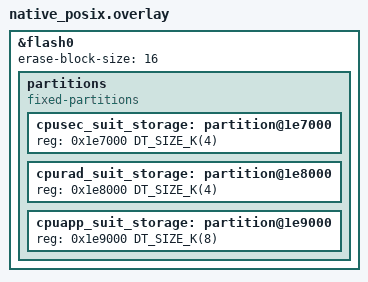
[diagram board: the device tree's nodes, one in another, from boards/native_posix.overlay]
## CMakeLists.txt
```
#
# Copyright (c) 2024 Nordic Semiconductor ASA
#
# SPDX-License-Identifier: LicenseRef-Nordic-5-Clause
#

cmake_minimum_required(VERSION 3.20.0)

find_package(Zephyr REQUIRED HINTS $ENV{ZEPHYR_BASE})

project(integration_test_suit_storage_nrf54h20)
include(../cmake/test_template.cmake)

target_include_directories(app PRIVATE
  ${SUIT_SUBSYS_DIR}/storage/include
)

target_sources(app PRIVATE
  ${SUIT_SUBSYS_DIR}/storage/src/suit_storage_encode.c
  ${SUIT_SUBSYS_DIR}/storage/src/suit_storage_envelope.c
  ${SUIT_SUBSYS_DIR}/storage/src/suit_storage_flags.c
  ${SUIT_SUBSYS_DIR}/storage/src/suit_storage_mpi.c
  # Use nRF54H20-specific implementation.
  ${SUIT_SUBSYS_DIR}/storage/src/suit_storage_nrf54h20.c
  ${SUIT_SUBSYS_DIR}/storage/src/suit_storage_nvv.c
  ${SUIT_SUBSYS_DIR}/storage/src/suit_storage_report.c
  ${SUIT_SUBSYS_DIR}/storage/src/suit_storage_update.c
  )

target_include_directories(app PRIVATE
  ${SUIT_SUBSYS_DIR}/storage/include
  )

zephyr_compile_definitions(
  CONFIG_SUIT_STORAGE_N_UPDATE_REGIONS=7
  CONFIG_SUIT_STORAGE_N_ENVELOPES=10
  CONFIG_SUIT_STORAGE_ENVELOPE_SIZE=2048
  CONFIG_SUIT_STORAGE_CONFIG_SIZE=128
  )

# Link with the CMake target, that includes SUIT platform internal APIs header
zephyr_library_link_libraries(suit_utils)
zephyr_library_link_libraries(suit_update_magic_values)
```

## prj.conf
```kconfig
#
# Copyright (c) 2024 Nordic Semiconductor ASA
#
# SPDX-License-Identifier: LicenseRef-Nordic-5-Clause
#

CONFIG_ZTEST=y

CONFIG_SUIT=y
CONFIG_SUIT_UTILS=y
CONFIG_SUIT_METADATA=y
# nRF54H20 storage uses SHA-256 to protect MPI and NVVs:
CONFIG_SUIT_CRYPTO=y

CONFIG_ZCBOR=y
CONFIG_ZCBOR_CANONICAL=y

CONFIG_FLASH=y
```

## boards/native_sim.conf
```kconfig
#
# Copyright (c) 2024 Nordic Semiconductor ASA
#
# SPDX-License-Identifier: LicenseRef-Nordic-5-Clause
#

CONFIG_FLASH_SIMULATOR=y
```

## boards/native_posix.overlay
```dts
/*
 * Copyright (c) 2024 Nordic Semiconductor ASA
 *
 * SPDX-License-Identifier: LicenseRef-Nordic-5-Clause
 */

&flash0 {
	/* Align erase block size with the nRF54H20 MRAM definition. */
	erase-block-size = <16>;

	partitions {
		compatible = "fixed-partitions";
		#address-cells = <1>;
		#size-cells = <1>;

		/* Use the last 32 kB of SecDom SUIT NVM storage. */
		/* Use the first 4kB as area reserved for Secure domain. */
		cpusec_suit_storage: partition@1e7000 {
			reg = <0x1e7000 DT_SIZE_K(4)>;
		};

		/* Use the next 4kB as area reserved for Radio domain. */
		cpurad_suit_storage: partition@1e8000 {
			reg = <0x1e8000 DT_SIZE_K(4)>;
		};

		/* Use the next 8kB as area reserved for Application domain. */
		cpuapp_suit_storage: partition@1e9000 {
			reg = <0x1e9000 DT_SIZE_K(8)>;
		};
	};
};
```

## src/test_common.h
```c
/*
 * Copyright (c) 2024 Nordic Semiconductor ASA
 *
 * SPDX-License-Identifier: LicenseRef-Nordic-5-Clause
 */

#include <suit_plat_mem_util.h>

#ifndef TEST_COMMON_H__
#define TEST_COMMON_H__

#define SUIT_STORAGE_NORDIC_ADDRESS suit_plat_mem_nvm_ptr_get(SUIT_STORAGE_NORDIC_OFFSET)
#define SUIT_STORAGE_NORDIC_OFFSET  FIXED_PARTITION_OFFSET(cpusec_suit_storage)
#define SUIT_STORAGE_NORDIC_SIZE    FIXED_PARTITION_SIZE(cpusec_suit_storage)
#define SUIT_STORAGE_RAD_ADDRESS    suit_plat_mem_nvm_ptr_get(SUIT_STORAGE_RAD_OFFSET)
#define SUIT_STORAGE_RAD_OFFSET	    FIXED_PARTITION_OFFSET(cpurad_suit_storage)
#define SUIT_STORAGE_RAD_SIZE	    FIXED_PARTITION_SIZE(cpurad_suit_storage)
#define SUIT_STORAGE_APP_ADDRESS    suit_plat_mem_nvm_ptr_get(SUIT_STORAGE_APP_OFFSET)
#define SUIT_STORAGE_APP_OFFSET	    FIXED_PARTITION_OFFSET(cpuapp_suit_storage)
#define SUIT_STORAGE_APP_SIZE	    FIXED_PARTITION_SIZE(cpuapp_suit_storage)

#define SUIT_STORAGE_APP_NVV_ADDRESS suit_plat_mem_nvm_ptr_get(SUIT_STORAGE_APP_NVV_OFFSET)
#define SUIT_STORAGE_APP_NVV_OFFSET  (SUIT_STORAGE_APP_OFFSET + 0x380)
#define SUIT_STORAGE_APP_NVV_SIZE    0x80
#define SUIT_STORAGE_APP_MPI_SIZE    0xf0
#define SUIT_STORAGE_APP_RFU_SIZE    0x230
#define SUIT_STORAGE_APP_UCI_SIZE    0x40
#define SUIT_STORAGE_RAD_MPI_SIZE    0x90
#define SUIT_STORAGE_DIGEST_SIZE     0x20

extern uint8_t nvv_empty[64];
extern uint8_t nvv_sample[64];

/** @brief Erase MPI area, assigned for Nordic-controlled manifests.
 */
void erase_area_nordic(void);

/** @brief Erase MPI area, assigned for radio core manifests.
 */
void erase_area_rad(void);

/** @brief Erase MPI area, assigned for application manifests.
 */
void erase_area_app(void);

/** @brief Erase part of MPI area, holding NVV values.
 */
void erase_area_app_nvv(void);

/** @brief Erase part of MPI area, holding NVV backup.
 */
void erase_area_app_nvv_backup(void);

/** @brief Populate part of MPI area, holding NVV backup with initial values.
 */
void write_area_app_empty_nvv_backup(void);

/** @brief Populate part of MPI area, holding NVV backup with sample values.
 */
void write_area_app_nvv_backup(void);

/** @brief Populate part of MPI area, holding NVV values with sample values.
 */
void write_area_app_nvv(void);

/** @brief Populate application MPI area, with ones and the correct digest.
 */
void write_empty_area_app(void);

/** @brief Populate radio MPI area, with ones and the correct digest.
 */
void write_empty_area_rad(void);

/** @brief Populate part of application MPI area, with sample root MPI.
 */
void write_area_app_root(void);

/** @brief Populate part of radio MPI area, with sample MPI entry.
 */
void write_area_rad(void);

/** @brief Populate part of Nordic MPI area, with sample root MPI backup.
 */
void write_area_nordic_root(void);

/** @brief Populate part of Nordic MPI area, with sample radio MPI entry backup.
 */
void write_area_nordic_rad(void);

/** @brief Populate part of Nordic MPI area, with sample outdated root MPI backup.
 */
void write_area_nordic_old_root(void);

/** @brief Populate part of Nordic MPI area, with sample outdated radio MPI backup.
 */
void write_area_nordic_old_rad(void);

/** @brief Assert that all Nordic-controlled MPIs are provisioned.
 */
void assert_nordic_classes(void);

/** @brief Assert that only Nordic classes are supported.
 */
void assert_only_nordic_classes(void);

/** @brief Assert that root MPI is provisioned.
 */
void assert_sample_root_class(void);

/** @brief Assert that root and sample radio MPI are provisioned.
 */
void assert_sample_root_rad_class(void);

/** @brief Assert that only sample radio MPI are provisioned.
 */
void assert_sample_rad_class(void);

/** @brief Assert that the application reserved area and update candidate information
 *         is purged.
 *
 * @param[in] addr  Address of the reserved area.
 * @param[in] size  Size of the reserved area and update candidate information (sum).
 */
void assert_purged_reserved_uci_area_app(uint8_t *addr, size_t size);

/** @brief Assert that the application MPI area is purged.
 *
 * @param[in] addr  Address of the area.
 * @param[in] size  Size of the area.
 */
void assert_purged_mpi_area_app(uint8_t *addr, size_t size);

/** @brief Assert that the area contains empty application MPI.
 *
 * @param[in] addr  Address of the area.
 * @param[in] size  Size of the area.
 */
void assert_empty_mpi_area_app(uint8_t *addr, size_t size);

/** @brief Assert that the area contains valid root MPI.
 *
 * @param[in] addr  Address of the area.
 * @param[in] size  Size of the area.
 */
void assert_valid_mpi_area_app(uint8_t *addr, size_t size);

/** @brief Assert that the radio MPI area is purged.
 *
 * @param[in] addr  Address of the area.
 * @param[in] size  Size of the area.
 */
void assert_purged_mpi_area_rad(uint8_t *addr, size_t size);

/** @brief Assert that the area contains empty radio MPI.
 *
 * @param[in] addr  Address of the area.
 * @param[in] size  Size of the area.
 */
void assert_empty_mpi_area_rad(uint8_t *addr, size_t size);

/** @brief Assert that the area contains valid sample radio MPI entry.
 *
 * @param[in] addr  Address of the area.
 * @param[in] size  Size of the area.
 */
void assert_valid_mpi_area_rad(uint8_t *addr, size_t size);

#endif /* TEST_COMMON_H__ */
```

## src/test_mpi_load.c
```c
/*
 * Copyright (c) 2024 Nordic Semiconductor ASA
 *
 * SPDX-License-Identifier: LicenseRef-Nordic-5-Clause
 */

#include <zephyr/ztest.h>
#include <suit_storage_mpi.h>
#include "test_common.h"

static void test_suite_before(void *f)
{
	/* Reinitialize MPI, so it clears all internal state variables. */
	suit_plat_err_t err = suit_storage_mpi_init();

	zassert_equal(err, SUIT_PLAT_SUCCESS, "Failed to init SUIT MPI module (%d)", err);
}

ZTEST_SUITE(suit_storage_nrf54h20_mpi_load_tests, NULL, NULL, test_suite_before, NULL, NULL);

ZTEST(suit_storage_nrf54h20_mpi_load_tests, test_vid_uuid_zeros)
{
	/* clang-format off */
	uint8_t mpi[] = {
		0x01, /* version */
		0x01, /* downgrade prevention disabled */
		0x02, /* Independent update allowed */
		0x01, /* signature check disabled */
		/* reserved (12) */
		0xFF, 0xFF, 0xFF, 0xFF,
		0xFF, 0xFF, 0xFF, 0xFF, 0xFF, 0xFF, 0xFF, 0xFF,
		/* 0x00 * 16 */
		0x00, 0x00, 0x00, 0x00, 0x00, 0x00, 0x00, 0x00,
		0x00, 0x00, 0x00, 0x00, 0x00, 0x00, 0x00, 0x00,
		/* RFC4122 uuid5(nordic_vid, 'test_sample_root') */
		0x97, 0x05, 0x48, 0x23, 0x4c, 0x3d, 0x59, 0xa1,
		0x89, 0x86, 0xa5, 0x46, 0x60, 0xa1, 0x4b, 0x0a,
	};
	/* clang-format on */

	suit_plat_err_t err =
		suit_storage_mpi_configuration_load(SUIT_MANIFEST_APP_ROOT, mpi, sizeof(mpi));
	zassert_equal(err, SUIT_PLAT_ERR_OUT_OF_BOUNDS,
		      "MPI with UUID filled with zeros should fail to load");
}

ZTEST(suit_storage_nrf54h20_mpi_load_tests, test_vid_uuid_ones)
{
	/* clang-format off */
	uint8_t mpi[] = {
		0x01, /* version */
		0x01, /* downgrade prevention disabled */
		0x02, /* Independent update allowed */
		0x01, /* signature check disabled */
		/* reserved (12) */
		0xFF, 0xFF, 0xFF, 0xFF,
		0xFF, 0xFF, 0xFF, 0xFF, 0xFF, 0xFF, 0xFF, 0xFF,
		/* 0xFF * 16 */
		0xFF, 0xFF, 0xFF, 0xFF, 0xFF, 0xFF, 0xFF, 0xFF,
		0xFF, 0xFF, 0xFF, 0xFF, 0xFF, 0xFF, 0xFF, 0xFF,
		/* RFC4122 uuid5(nordic_vid, 'test_sample_root') */
		0x97, 0x05, 0x48, 0x23, 0x4c, 0x3d, 0x59, 0xa1,
		0x89, 0x86, 0xa5, 0x46, 0x60, 0xa1, 0x4b, 0x0a,
	};
	/* clang-format on */

	suit_plat_err_t err =
		suit_storage_mpi_configuration_load(SUIT_MANIFEST_APP_ROOT, mpi, sizeof(mpi));
	zassert_equal(err, SUIT_PLAT_ERR_OUT_OF_BOUNDS,
		      "MPI with UUID filled with ones should fail to load");
}

ZTEST(suit_storage_nrf54h20_mpi_load_tests, test_cid_uuid_zeros)
{
	/* clang-format off */
	uint8_t mpi[] = {
		0x01, /* version */
		0x01, /* downgrade prevention disabled */
		0x02, /* Independent update allowed */
		0x01, /* signature check disabled */
		/* reserved (12) */
		0xFF, 0xFF, 0xFF, 0xFF,
		0xFF, 0xFF, 0xFF, 0xFF, 0xFF, 0xFF, 0xFF, 0xFF,
		/* RFC4122 uuid5(uuid.NAMESPACE_DNS, 'nordicsemi.com') */
		0x76, 0x17, 0xda, 0xa5, 0x71, 0xfd, 0x5a, 0x85,
		0x8f, 0x94, 0xe2, 0x8d, 0x73, 0x5c, 0xe9, 0xf4,
		/* 0x00 * 16 */
		0x00, 0x00, 0x00, 0x00, 0x00, 0x00, 0x00, 0x00,
		0x00, 0x00, 0x00, 0x00, 0x00, 0x00, 0x00, 0x00,
	};
	/* clang-format on */

	suit_plat_err_t err =
		suit_storage_mpi_configuration_load(SUIT_MANIFEST_APP_ROOT, mpi, sizeof(mpi));
	zassert_equal(err, SUIT_PLAT_ERR_OUT_OF_BOUNDS,
		      "MPI with UUID filled with zeros should fail to load");
}

ZTEST(suit_storage_nrf54h20_mpi_load_tests, test_cid_uuid_ones)
{
	/* clang-format off */
	uint8_t mpi[] = {
		0x01, /* version */
		0x01, /* downgrade prevention disabled */
		0x02, /* Independent update allowed */
		0x01, /* signature check disabled */
		/* reserved (12) */
		0xFF, 0xFF, 0xFF, 0xFF,
		0xFF, 0xFF, 0xFF, 0xFF, 0xFF, 0xFF, 0xFF, 0xFF,
		/* RFC4122 uuid5(uuid.NAMESPACE_DNS, 'nordicsemi.com') */
		0x76, 0x17, 0xda, 0xa5, 0x71, 0xfd, 0x5a, 0x85,
		0x8f, 0x94, 0xe2, 0x8d, 0x73, 0x5c, 0xe9, 0xf4,
		/* 0xFF * 16 */
		0xFF, 0xFF, 0xFF, 0xFF, 0xFF, 0xFF, 0xFF, 0xFF,
		0xFF, 0xFF, 0xFF, 0xFF, 0xFF, 0xFF, 0xFF, 0xFF,
	};
	/* clang-format on */

	suit_plat_err_t err =
		suit_storage_mpi_configuration_load(SUIT_MANIFEST_APP_ROOT, mpi, sizeof(mpi));
	zassert_equal(err, SUIT_PLAT_ERR_OUT_OF_BOUNDS,
		      "MPI with UUID filled with ones should fail to load");
}

ZTEST(suit_storage_nrf54h20_mpi_load_tests, test_recovery_without_updates)
{
	/* clang-format off */
	uint8_t mpi[] = {
		0x01, /* version */
		0x01, /* downgrade prevention disabled */
		0x01, /* Independent update disabled */
		0x01, /* signature check disabled */
		/* reserved (12) */
		0xFF, 0xFF, 0xFF, 0xFF,
		0xFF, 0xFF, 0xFF, 0xFF, 0xFF, 0xFF, 0xFF, 0xFF,
		/* RFC4122 uuid5(uuid.NAMESPACE_DNS, 'nordicsemi.com') */
		0x76, 0x17, 0xda, 0xa5, 0x71, 0xfd, 0x5a, 0x85,
		0x8f, 0x94, 0xe2, 0x8d, 0x73, 0x5c, 0xe9, 0xf4,
		/* RFC4122 uuid5(nordic_vid, 'test_sample_root') */
		0x97, 0x05, 0x48, 0x23, 0x4c, 0x3d, 0x59, 0xa1,
		0x89, 0x86, 0xa5, 0x46, 0x60, 0xa1, 0x4b, 0x0a,
	};
	/* clang-format on */

	suit_plat_err_t err =
		suit_storage_mpi_configuration_load(SUIT_MANIFEST_APP_RECOVERY, mpi, sizeof(mpi));
	zassert_equal(err, SUIT_PLAT_ERR_UNSUPPORTED,
		      "It should not be possible to block application recovery updates");
}

ZTEST(suit_storage_nrf54h20_mpi_load_tests, test_root_without_updates)
{
	/* clang-format off */
	uint8_t mpi[] = {
		0x01, /* version */
		0x01, /* downgrade prevention disabled */
		0x01, /* Independent update disabled */
		0x01, /* signature check disabled */
		/* reserved (12) */
		0xFF, 0xFF, 0xFF, 0xFF,
		0xFF, 0xFF, 0xFF, 0xFF, 0xFF, 0xFF, 0xFF, 0xFF,
		/* RFC4122 uuid5(uuid.NAMESPACE_DNS, 'nordicsemi.com') */
		0x76, 0x17, 0xda, 0xa5, 0x71, 0xfd, 0x5a, 0x85,
		0x8f, 0x94, 0xe2, 0x8d, 0x73, 0x5c, 0xe9, 0xf4,
		/* RFC4122 uuid5(nordic_vid, 'test_sample_root') */
		0x97, 0x05, 0x48, 0x23, 0x4c, 0x3d, 0x59, 0xa1,
		0x89, 0x86, 0xa5, 0x46, 0x60, 0xa1, 0x4b, 0x0a,
	};
	/* clang-format on */

	suit_plat_err_t err =
		suit_storage_mpi_configuration_load(SUIT_MANIFEST_APP_ROOT, mpi, sizeof(mpi));
	zassert_equal(err, SUIT_PLAT_ERR_UNSUPPORTED,
		      "It should not be possible to block application root updates");
}

ZTEST(suit_storage_nrf54h20_mpi_load_tests, test_nonerased_reserved)
{
	/* clang-format off */
	uint8_t mpi[] = {
		0x01, /* version */
		0x01, /* downgrade prevention disabled */
		0x02, /* Independent update allowed */
		0x01, /* signature check disabled */
		/* reserved (12) */
		0xFF, 0xFF, 0xFF, 0xFF,
		0xFF, 0xFF, 0xFF, 0xFF, 0xFF, 0xFF, 0xFF, 0xFE,
		/* RFC4122 uuid5(uuid.NAMESPACE_DNS, 'nordicsemi.com') */
		0x76, 0x17, 0xda, 0xa5, 0x71, 0xfd, 0x5a, 0x85,
		0x8f, 0x94, 0xe2, 0x8d, 0x73, 0x5c, 0xe9, 0xf4,
		/* RFC4122 uuid5(nordic_vid, 'test_sample_root') */
		0x97, 0x05, 0x48, 0x23, 0x4c, 0x3d, 0x59, 0xa1,
		0x89, 0x86, 0xa5, 0x46, 0x60, 0xa1, 0x4b, 0x0a,
	};
	/* clang-format on */

	suit_plat_err_t err =
		suit_storage_mpi_configuration_load(SUIT_MANIFEST_APP_ROOT, mpi, sizeof(mpi));
	zassert_equal(err, SUIT_PLAT_ERR_OUT_OF_BOUNDS,
		      "It should not be possible to load MPI with nonerase reserved fields");
}

ZTEST(suit_storage_nrf54h20_mpi_load_tests, test_empty_new_version)
{
	/* clang-format off */
	uint8_t mpi[] = {
		0x02, /* unsupported version */
		0xFF, 0xFF, 0xFF, 0xFF, 0xFF, 0xFF, 0xFF,
		0xFF, 0xFF, 0xFF, 0xFF, 0xFF, 0xFF, 0xFF, 0xFF,
		0xFF, 0xFF, 0xFF, 0xFF, 0xFF, 0xFF, 0xFF, 0xFF,
		0xFF, 0xFF, 0xFF, 0xFF, 0xFF, 0xFF, 0xFF, 0xFF,
		0xFF, 0xFF, 0xFF, 0xFF, 0xFF, 0xFF, 0xFF, 0xFF,
		0xFF, 0xFF, 0xFF, 0xFF, 0xFF, 0xFF, 0xFF, 0xFF,
	};
	/* clang-format on */

	suit_plat_err_t err =
		suit_storage_mpi_configuration_load(SUIT_MANIFEST_APP_ROOT, mpi, sizeof(mpi));
	zassert_equal(err, SUIT_PLAT_ERR_OUT_OF_BOUNDS,
		      "It should not be possible to load MPI with unsupported version");
}

ZTEST(suit_storage_nrf54h20_mpi_load_tests, test_downgrade_prevention_zero)
{
	/* clang-format off */
	uint8_t mpi[] = {
		0x01, /* version */
		0x00, /* unknown downgrade prevention policy */
		0x02, /* Independent update allowed */
		0x01, /* signature check disabled */
		/* reserved (12) */
		0xFF, 0xFF, 0xFF, 0xFF,
		0xFF, 0xFF, 0xFF, 0xFF, 0xFF, 0xFF, 0xFF, 0xFF,
		/* RFC4122 uuid5(uuid.NAMESPACE_DNS, 'nordicsemi.com') */
		0x76, 0x17, 0xda, 0xa5, 0x71, 0xfd, 0x5a, 0x85,
		0x8f, 0x94, 0xe2, 0x8d, 0x73, 0x5c, 0xe9, 0xf4,
		/* RFC4122 uuid5(nordic_vid, 'test_sample_root') */
		0x97, 0x05, 0x48, 0x23, 0x4c, 0x3d, 0x59, 0xa1,
		0x89, 0x86, 0xa5, 0x46, 0x60, 0xa1, 0x4b, 0x0a,
	};
	/* clang-format on */

	suit_plat_err_t err =
		suit_storage_mpi_configuration_load(SUIT_MANIFEST_APP_ROOT, mpi, sizeof(mpi));
	zassert_equal(
		err, SUIT_PLAT_ERR_OUT_OF_BOUNDS,
		"It should not be possible to load MPI with unknown downgrade prevention policy");
}

ZTEST(suit_storage_nrf54h20_mpi_load_tests, test_independent_updateability_zero)
{
	/* clang-format off */
	uint8_t mpi[] = {
		0x01, /* version */
		0x01, /* downgrade prevention disabled */
		0x00, /* unknown independent update policy */
		0x01, /* signature check disabled */
		/* reserved (12) */
		0xFF, 0xFF, 0xFF, 0xFF,
		0xFF, 0xFF, 0xFF, 0xFF, 0xFF, 0xFF, 0xFF, 0xFF,
		/* RFC4122 uuid5(uuid.NAMESPACE_DNS, 'nordicsemi.com') */
		0x76, 0x17, 0xda, 0xa5, 0x71, 0xfd, 0x5a, 0x85,
		0x8f, 0x94, 0xe2, 0x8d, 0x73, 0x5c, 0xe9, 0xf4,
		/* RFC4122 uuid5(nordic_vid, 'test_sample_root') */
		0x97, 0x05, 0x48, 0x23, 0x4c, 0x3d, 0x59, 0xa1,
		0x89, 0x86, 0xa5, 0x46, 0x60, 0xa1, 0x4b, 0x0a,
	};
	/* clang-format on */

	suit_plat_err_t err =
		suit_storage_mpi_configuration_load(SUIT_MANIFEST_APP_ROOT, mpi, sizeof(mpi));
	zassert_equal(
		err, SUIT_PLAT_ERR_OUT_OF_BOUNDS,
		"It should not be possible to load MPI with unknown independent update policy");
}

ZTEST(suit_storage_nrf54h20_mpi_load_tests, test_signature_check_zero)
{
	/* clang-format off */
	uint8_t mpi[] = {
		0x01, /* version */
		0x01, /* downgrade prevention disabled */
		0x02, /* Independent update allowed */
		0x00, /* unknown signature check policy */
		/* reserved (12) */
		0xFF, 0xFF, 0xFF, 0xFF,
		0xFF, 0xFF, 0xFF, 0xFF, 0xFF, 0xFF, 0xFF, 0xFF,
		/* RFC4122 uuid5(uuid.NAMESPACE_DNS, 'nordicsemi.com') */
		0x76, 0x17, 0xda, 0xa5, 0x71, 0xfd, 0x5a, 0x85,
		0x8f, 0x94, 0xe2, 0x8d, 0x73, 0x5c, 0xe9, 0xf4,
		/* RFC4122 uuid5(nordic_vid, 'test_sample_root') */
		0x97, 0x05, 0x48, 0x23, 0x4c, 0x3d, 0x59, 0xa1,
		0x89, 0x86, 0xa5, 0x46, 0x60, 0xa1, 0x4b, 0x0a,
	};
	/* clang-format on */

	suit_plat_err_t err =
		suit_storage_mpi_configuration_load(SUIT_MANIFEST_APP_ROOT, mpi, sizeof(mpi));
	zassert_equal(err, SUIT_PLAT_ERR_OUT_OF_BOUNDS,
		      "It should not be possible to load MPI with unknown signature check policy");
}

ZTEST(suit_storage_nrf54h20_mpi_load_tests, test_fake_nordic_top_manifest)
{
	/* clang-format off */
	uint8_t mpi[] = {
		0x01, /* version */
		0x01, /* downgrade prevention disabled */
		0x02, /* Independent update allowed */
		0x01, /* signature check disabled */
		/* reserved (12) */
		0xFF, 0xFF, 0xFF, 0xFF,
		0xFF, 0xFF, 0xFF, 0xFF, 0xFF, 0xFF, 0xFF, 0xFF,
		/* RFC4122 uuid5(uuid.NAMESPACE_DNS, 'nordicsemi.com') */
		0x76, 0x17, 0xda, 0xa5, 0x71, 0xfd, 0x5a, 0x85,
		0x8f, 0x94, 0xe2, 0x8d, 0x73, 0x5c, 0xe9, 0xf4,
		/* RFC4122 uuid5(nordic_vid, 'nRF54H20_nordic_top') */
		0xf0, 0x3d, 0x38, 0x5e, 0xa7, 0x31, 0x56, 0x05,
		0xb1, 0x5d, 0x03, 0x7f, 0x6d, 0xa6, 0x09, 0x7f,
	};
	/* clang-format on */

	/* GIVEN the Nordic top manifest is already loaded */
	suit_plat_err_t err =
		suit_storage_mpi_configuration_load(SUIT_MANIFEST_SEC_TOP, mpi, sizeof(mpi));
	zassert_equal(err, SUIT_PLAT_SUCCESS,
		      "Unable to load Nordic top manifest prior test execution (err: %d)", err);

	/* WHEN application loads ROOT manifest with Nordic top class ID */
	err = suit_storage_mpi_configuration_load(SUIT_MANIFEST_APP_ROOT, mpi, sizeof(mpi));

	/* THEN application slot is not loaded */
	zassert_equal(err, SUIT_PLAT_ERR_EXISTS,
		      "It should not be possible to load root MPI with Nordic top class ID");
}

ZTEST(suit_storage_nrf54h20_mpi_load_tests, test_two_root_manifests)
{
	/* clang-format off */
	uint8_t mpi[] = {
		0x01, /* version */
		0x01, /* downgrade prevention disabled */
		0x02, /* Independent update allowed */
		0x01, /* signature check disabled */
		/* reserved (12) */
		0xFF, 0xFF, 0xFF, 0xFF,
		0xFF, 0xFF, 0xFF, 0xFF, 0xFF, 0xFF, 0xFF, 0xFF,
		/* RFC4122 uuid5(uuid.NAMESPACE_DNS, 'nordicsemi.com') */
		0x76, 0x17, 0xda, 0xa5, 0x71, 0xfd, 0x5a, 0x85,
		0x8f, 0x94, 0xe2, 0x8d, 0x73, 0x5c, 0xe9, 0xf4,
		/* RFC4122 uuid5(nordic_vid, 'test_sample_root') */
		0x97, 0x05, 0x48, 0x23, 0x4c, 0x3d, 0x59, 0xa1,
		0x89, 0x86, 0xa5, 0x46, 0x60, 0xa1, 0x4b, 0x0a,
	};
	/* clang-format on */

	/* GIVEN the ROOT manifest is already loaded */
	suit_plat_err_t err =
		suit_storage_mpi_configuration_load(SUIT_MANIFEST_APP_ROOT, mpi, sizeof(mpi));
	zassert_equal(err, SUIT_PLAT_SUCCESS,
		      "Unable to load root manifest prior test execution (err: %d)", err);

	/* WHEN application loads ROOT manifest from a different slot */
	err = suit_storage_mpi_configuration_load(SUIT_MANIFEST_APP_ROOT, mpi, sizeof(mpi));

	/* THEN the second slot is not loaded */
	zassert_equal(err, SUIT_PLAT_ERR_EXISTS,
		      "It should not be possible to load root MPI twice");
}

ZTEST(suit_storage_nrf54h20_mpi_load_tests, test_too_many_roles)
{
	/* clang-format off */
	suit_manifest_role_t roles[] = {
		SUIT_MANIFEST_SEC_TOP,
		SUIT_MANIFEST_SEC_SDFW,
		SUIT_MANIFEST_SEC_SYSCTRL,
		SUIT_MANIFEST_APP_ROOT,
		SUIT_MANIFEST_APP_RECOVERY,
		SUIT_MANIFEST_APP_LOCAL_1,
		SUIT_MANIFEST_APP_LOCAL_2,
		SUIT_MANIFEST_APP_LOCAL_3,
		SUIT_MANIFEST_RAD_RECOVERY,
		SUIT_MANIFEST_RAD_LOCAL_1,
		SUIT_MANIFEST_RAD_LOCAL_2,
	};
	uint8_t mpi[] = {
		0x01, /* version */
		0x01, /* downgrade prevention disabled */
		0x02, /* Independent update allowed */
		0x01, /* signature check disabled */
		/* reserved (12) */
		0xFF, 0xFF, 0xFF, 0xFF,
		0xFF, 0xFF, 0xFF, 0xFF, 0xFF, 0xFF, 0xFF, 0xFF,
		/* RFC4122 uuid5(uuid.NAMESPACE_DNS, 'nordicsemi.com') */
		0x76, 0x17, 0xda, 0xa5, 0x71, 0xfd, 0x5a, 0x85,
		0x8f, 0x94, 0xe2, 0x8d, 0x73, 0x5c, 0xe9, 0xf4,
		/* RFC4122 uuid5(nordic_vid, 'test_sample_root') */
		0x97, 0x05, 0x48, 0x23, 0x4c, 0x3d, 0x59, 0xa1,
		0x89, 0x86, 0xa5, 0x46, 0x60, 0xa1, 0x4b, 0x0a,
	};
	uint8_t mpi_array[sizeof(mpi) * ARRAY_SIZE(roles)];
	/* clang-format on */

	for (size_t i = 0; i < ARRAY_SIZE(roles); i++) {
		/* Fake CID so each entry is different */
		memcpy(&mpi_array[i * sizeof(mpi)], mpi, sizeof(mpi));
		mpi_array[i * sizeof(mpi) + sizeof(mpi) - 1] = roles[i];
	}

	/* Check that the test will not exceed the array with roles. */
	zassert_true(ARRAY_SIZE(roles) > CONFIG_SUIT_STORAGE_N_ENVELOPES,
		     "Unable to execute test: role list does not exceed MPI limits (%d >= %d)",
		     CONFIG_SUIT_STORAGE_N_ENVELOPES, ARRAY_SIZE(roles));

	/* GIVEN all slots in MPI are used */
	for (size_t i = 0; i < CONFIG_SUIT_STORAGE_N_ENVELOPES; i++) {
		suit_plat_err_t err = suit_storage_mpi_configuration_load(
			roles[i], &mpi_array[i * sizeof(mpi)], sizeof(mpi));
		zassert_equal(err, SUIT_PLAT_SUCCESS,
			      "Unable to load manifest with role %d at index %d prior test "
			      "execution (err: %d)",
			      roles[i], i, err);
	}

	for (size_t i = CONFIG_SUIT_STORAGE_N_ENVELOPES; i < ARRAY_SIZE(roles); i++) {
		/* WHEN application loads next manifest */
		suit_plat_err_t err = suit_storage_mpi_configuration_load(
			roles[i], &mpi_array[i * sizeof(mpi)], sizeof(mpi));

		/* THEN the it is not loaded */
		zassert_equal(
			err, SUIT_PLAT_ERR_SIZE,
			"It should not be possible to load more MPIs than configured (index: %d)",
			i);
	}
}
```

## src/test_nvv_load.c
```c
/*
 * Copyright (c) 2024 Nordic Semiconductor ASA
 *
 * SPDX-License-Identifier: LicenseRef-Nordic-5-Clause
 */

#include <zephyr/ztest.h>
#include <suit_storage.h>
#include <suit_storage_mpi.h>
#include <suit_storage_nvv.h>
#include "test_common.h"

ZTEST_SUITE(suit_storage_nrf54h20_nvv_tests, NULL, NULL, NULL, NULL, NULL);

ZTEST(suit_storage_nrf54h20_nvv_tests, test_app_nvv_read)
{
	/* GIVEN the device is provisioned with application MPI with root config */
	erase_area_nordic();
	write_area_nordic_root();
	erase_area_rad();
	erase_area_app();
	write_area_app_root();
	/* .. and NVV is present */
	write_area_app_nvv();
	/* .. and NVV backup is present */
	write_area_app_nvv_backup();

	/* ... and storage module is initialized */
	int err = suit_storage_init();

	/* ... and digest of the application MPI matches... */
	/* ... and the application MPI is the same as application backup area */
	assert_valid_mpi_area_app(SUIT_STORAGE_APP_ADDRESS,
				  SUIT_STORAGE_APP_MPI_SIZE + SUIT_STORAGE_DIGEST_SIZE);
	assert_valid_mpi_area_app(SUIT_STORAGE_NORDIC_ADDRESS + SUIT_STORAGE_RAD_MPI_SIZE +
					  SUIT_STORAGE_DIGEST_SIZE,
				  SUIT_STORAGE_APP_MPI_SIZE + SUIT_STORAGE_DIGEST_SIZE);
	/* ... and parsing of the root MPI succeeds */
	int exp_err = SUIT_PLAT_SUCCESS;
	/* ... and NVV area digest matches */
	/* ... and NVV area is not modified */
	zassert_mem_equal(SUIT_STORAGE_APP_NVV_ADDRESS, nvv_sample, SUIT_STORAGE_APP_NVV_SIZE / 2);
	/* ... and NVV area backup is not modified */
	zassert_mem_equal(SUIT_STORAGE_APP_NVV_ADDRESS + SUIT_STORAGE_APP_NVV_SIZE / 2, nvv_sample,
			  SUIT_STORAGE_APP_NVV_SIZE / 2);
	/* ... and initialization succeeds */
	zassert_equal(err, exp_err, "Failed to initialize SUIT storage (%d).", err);
	/* ... and Nordic class IDs are supported */
	assert_nordic_classes();
	/* ... and sample root class is supported */
	assert_sample_root_class();

	uint8_t constants[SUIT_STORAGE_NVV_N_VARS] = {
		0x00, 0x00, 0x00, 0x00, 0xAA, 0xAA, 0xAA, 0xAA,
		0xAA, 0x55, 0xAA, 0x55, 0x00, 0x00, 0x00, 0x01,
		0x01, 0x00, 0x00, 0x00, 0xFF, 0xFF, 0xFF, 0xFF,
		0xAB, 0xCD, 0xEF, 0x98, 0xFF, 0xFF, 0xFF, 0xFF,
	};
	for (size_t i = 0; i < SUIT_STORAGE_NVV_N_VARS; i++) {
		uint8_t value;

		/* WHEN the NVV value is read */
		err = suit_storage_var_get(i, &value);
		/* THEN the NVV read succeeds */
		zassert_equal(err, SUIT_PLAT_SUCCESS, "Failed to read NVV at index: %d (%d).", i,
			      err);
		/* ... and values in NVV area matches the preconfigured constants */
		zassert_equal(value, constants[i], "Invalid NVV value at index: %d (0x%X != 0x%X).",
			      i, value, constants[i]);
	}
}

ZTEST(suit_storage_nrf54h20_nvv_tests, test_app_nvv_write)
{
	/* GIVEN the device is provisioned with application MPI with root config */
	erase_area_nordic();
	write_area_nordic_root();
	/* .. and NVV area is erased */
	erase_area_rad();
	erase_area_app();
	write_area_app_root();

	/* ... and storage module is initialized */
	int err = suit_storage_init();

	/* ... and digest of the application MPI matches... */
	/* ... and the application MPI is the same as application backup area */
	assert_valid_mpi_area_app(SUIT_STORAGE_APP_ADDRESS,
				  SUIT_STORAGE_APP_MPI_SIZE + SUIT_STORAGE_DIGEST_SIZE);
	assert_valid_mpi_area_app(SUIT_STORAGE_NORDIC_ADDRESS + SUIT_STORAGE_RAD_MPI_SIZE +
					  SUIT_STORAGE_DIGEST_SIZE,
				  SUIT_STORAGE_APP_MPI_SIZE + SUIT_STORAGE_DIGEST_SIZE);
	/* ... and parsing of the root MPI succeeds */
	int exp_err = SUIT_PLAT_SUCCESS;
	/* ... and NVV area digest does not match */
	/* ... and NVV area is initialized with default values (0xFF) and digest */
	zassert_mem_equal(SUIT_STORAGE_APP_NVV_ADDRESS, nvv_empty, SUIT_STORAGE_APP_NVV_SIZE / 2);
	/* ... and NVV area is copied into NVV backup area */
	zassert_mem_equal(SUIT_STORAGE_APP_NVV_ADDRESS + SUIT_STORAGE_APP_NVV_SIZE / 2, nvv_empty,
			  SUIT_STORAGE_APP_NVV_SIZE / 2);
	/* ... and initialization succeeds */
	zassert_equal(err, exp_err, "Failed to initialize SUIT storage (%d).", err);
	/* ... and Nordic class IDs are supported */
	assert_nordic_classes();
	/* ... and sample root class is supported */
	assert_sample_root_class();

	/* ... and NVV is set with initial values */
	for (size_t i = 0; i < SUIT_STORAGE_NVV_N_VARS; i++) {
		uint8_t value;

		err = suit_storage_var_get(i, &value);
		zassert_equal(err, SUIT_PLAT_SUCCESS, "Failed to read NVV at index: %d (%d).", i,
			      err);
		zassert_equal(value, 0xFF,
			      "Invalid initial NVV value at index: %d (0x%X != 0x%X).", i, value,
			      0xFF);
	}

	/* WHEN NVV variables are updated */
	uint8_t constants[SUIT_STORAGE_NVV_N_VARS] = {
		0x00, 0x00, 0x00, 0x00, 0xAA, 0xAA, 0xAA, 0xAA,
		0xAA, 0x55, 0xAA, 0x55, 0x00, 0x00, 0x00, 0x01,
		0x01, 0x00, 0x00, 0x00, 0xFF, 0xFF, 0xFF, 0xFF,
		0xAB, 0xCD, 0xEF, 0x98, 0xFF, 0xFF, 0xFF, 0xFF,
	};
	for (size_t i = 0; i < SUIT_STORAGE_NVV_N_VARS; i++) {
		err = suit_storage_var_set(i, constants[i]);
		zassert_equal(err, SUIT_PLAT_SUCCESS, "Failed to write NVV at index: %d (%d).", i,
			      err);
	}

	/* THEN value of NVV area matches the preconfigured constants */
	zassert_mem_equal(SUIT_STORAGE_APP_NVV_ADDRESS, nvv_sample, SUIT_STORAGE_APP_NVV_SIZE / 2);
	/* ... and value of NVV area backup is updated */
	zassert_mem_equal(SUIT_STORAGE_APP_NVV_ADDRESS + SUIT_STORAGE_APP_NVV_SIZE / 2, nvv_sample,
			  SUIT_STORAGE_APP_NVV_SIZE / 2);
}

ZTEST(suit_storage_nrf54h20_nvv_tests, test_app_nvv_ro_backup_read)
{
	/* GIVEN the device is provisioned with application MPI with root config */
	erase_area_nordic();
	write_area_nordic_root();
	erase_area_rad();
	erase_area_app();
	write_area_app_root();
	/* .. and NVV is present */
	write_area_app_nvv();
	/* .. and NVV backup is present */
	write_area_app_nvv_backup();

	/* ... and storage module is initialized */
	int err = suit_storage_init();

	/* ... and digest of the application MPI matches... */
	/* ... and the application MPI is the same as application backup area */
	assert_valid_mpi_area_app(SUIT_STORAGE_APP_ADDRESS,
				  SUIT_STORAGE_APP_MPI_SIZE + SUIT_STORAGE_DIGEST_SIZE);
	assert_valid_mpi_area_app(SUIT_STORAGE_NORDIC_ADDRESS + SUIT_STORAGE_RAD_MPI_SIZE +
					  SUIT_STORAGE_DIGEST_SIZE,
				  SUIT_STORAGE_APP_MPI_SIZE + SUIT_STORAGE_DIGEST_SIZE);
	/* ... and parsing of the root MPI succeeds */
	int exp_err = SUIT_PLAT_SUCCESS;
	/* ... and NVV area digest matches */
	/* ... and NVV area is not modified */
	zassert_mem_equal(SUIT_STORAGE_APP_NVV_ADDRESS, nvv_sample, SUIT_STORAGE_APP_NVV_SIZE / 2);
	/* ... and NVV area backup is not modified */
	zassert_mem_equal(SUIT_STORAGE_APP_NVV_ADDRESS + SUIT_STORAGE_APP_NVV_SIZE / 2, nvv_sample,
			  SUIT_STORAGE_APP_NVV_SIZE / 2);
	/* ... and initialization succeeds */
	zassert_equal(err, exp_err, "Failed to initialize SUIT storage (%d).", err);
	/* ... and Nordic class IDs are supported */
	assert_nordic_classes();
	/* ... and sample root class is supported */
	assert_sample_root_class();

	/* ... and NVV backup is corrupted after initialization*/
	erase_area_app_nvv_backup();

	uint8_t constants[SUIT_STORAGE_NVV_N_VARS] = {
		0x00, 0x00, 0x00, 0x00, 0xAA, 0xAA, 0xAA, 0xAA,
		0xAA, 0x55, 0xAA, 0x55, 0x00, 0x00, 0x00, 0x01,
		0x01, 0x00, 0x00, 0x00, 0xFF, 0xFF, 0xFF, 0xFF,
		0xAB, 0xCD, 0xEF, 0x98, 0xFF, 0xFF, 0xFF, 0xFF,
	};
	for (size_t i = 0; i < SUIT_STORAGE_NVV_N_VARS; i++) {
		uint8_t value;

		/* WHEN the NVV value is read */
		err = suit_storage_var_get(i, &value);
		/* THEN the NVV read succeeds */
		zassert_equal(err, SUIT_PLAT_SUCCESS, "Failed to read NVV at index: %d (%d).", i,
			      err);
		/* ... and values in NVV area matches the preconfigured constants */
		zassert_equal(value, constants[i], "Invalid NVV value at index: %d (0x%X != 0x%X).",
			      i, value, constants[i]);
	}
}

ZTEST(suit_storage_nrf54h20_nvv_tests, test_app_nvv_ro_backup_write)
{
	/* GIVEN the device is provisioned with application MPI with root config */
	erase_area_nordic();
	write_area_nordic_root();
	erase_area_rad();
	erase_area_app();
	write_area_app_root();
	/* .. and NVV is present */
	write_area_app_nvv();
	/* .. and NVV backup is present */
	write_area_app_nvv_backup();

	/* ... and storage module is initialized */
	int err = suit_storage_init();

	/* ... and digest of the application MPI matches... */
	/* ... and the application MPI is the same as application backup area */
	assert_valid_mpi_area_app(SUIT_STORAGE_APP_ADDRESS,
				  SUIT_STORAGE_APP_MPI_SIZE + SUIT_STORAGE_DIGEST_SIZE);
	assert_valid_mpi_area_app(SUIT_STORAGE_NORDIC_ADDRESS + SUIT_STORAGE_RAD_MPI_SIZE +
					  SUIT_STORAGE_DIGEST_SIZE,
				  SUIT_STORAGE_APP_MPI_SIZE + SUIT_STORAGE_DIGEST_SIZE);
	/* ... and parsing of the root MPI succeeds */
	int exp_err = SUIT_PLAT_SUCCESS;
	/* ... and NVV area digest matches */
	/* ... and NVV area is not modified */
	zassert_mem_equal(SUIT_STORAGE_APP_NVV_ADDRESS, nvv_sample, SUIT_STORAGE_APP_NVV_SIZE / 2);
	/* ... and NVV area backup is not modified */
	zassert_mem_equal(SUIT_STORAGE_APP_NVV_ADDRESS + SUIT_STORAGE_APP_NVV_SIZE / 2, nvv_sample,
			  SUIT_STORAGE_APP_NVV_SIZE / 2);
	/* ... and initialization succeeds */
	zassert_equal(err, exp_err, "Failed to initialize SUIT storage (%d).", err);
	/* ... and Nordic class IDs are supported */
	assert_nordic_classes();
	/* ... and sample root class is supported */
	assert_sample_root_class();

	/* ... and NVV backup is corrupted after initialization*/
	erase_area_app_nvv_backup();

	/* WHEN NVV variable is updated */
	err = suit_storage_var_set(0, 0x00);

	/* THEN the NVV update succeeds */
	zassert_equal(err, SUIT_PLAT_SUCCESS, "Failed to write NVV at index: 0 (%d).", err);

	/* ... and NVV area backup is recovered */
	zassert_mem_equal(SUIT_STORAGE_APP_NVV_ADDRESS + SUIT_STORAGE_APP_NVV_SIZE / 2, nvv_sample,
			  SUIT_STORAGE_APP_NVV_SIZE / 2);
}

ZTEST(suit_storage_nrf54h20_nvv_tests, test_app_nvv_ro_read)
{
	/* GIVEN the device is provisioned with application MPI with root config */
	erase_area_nordic();
	write_area_nordic_root();
	erase_area_rad();
	erase_area_app();
	write_area_app_root();
	/* .. and NVV is present */
	write_area_app_nvv();
	/* .. and NVV backup is present */
	write_area_app_nvv_backup();

	/* ... and storage module is initialized */
	int err = suit_storage_init();

	/* ... and digest of the application MPI matches... */
	/* ... and the application MPI is the same as application backup area */
	assert_valid_mpi_area_app(SUIT_STORAGE_APP_ADDRESS,
				  SUIT_STORAGE_APP_MPI_SIZE + SUIT_STORAGE_DIGEST_SIZE);
	assert_valid_mpi_area_app(SUIT_STORAGE_NORDIC_ADDRESS + SUIT_STORAGE_RAD_MPI_SIZE +
					  SUIT_STORAGE_DIGEST_SIZE,
				  SUIT_STORAGE_APP_MPI_SIZE + SUIT_STORAGE_DIGEST_SIZE);
	/* ... and parsing of the root MPI succeeds */
	int exp_err = SUIT_PLAT_SUCCESS;
	/* ... and NVV area digest matches */
	/* ... and NVV area is not modified */
	zassert_mem_equal(SUIT_STORAGE_APP_NVV_ADDRESS, nvv_sample, SUIT_STORAGE_APP_NVV_SIZE / 2);
	/* ... and NVV area backup is not modified */
	zassert_mem_equal(SUIT_STORAGE_APP_NVV_ADDRESS + SUIT_STORAGE_APP_NVV_SIZE / 2, nvv_sample,
			  SUIT_STORAGE_APP_NVV_SIZE / 2);
	/* ... and initialization succeeds */
	zassert_equal(err, exp_err, "Failed to initialize SUIT storage (%d).", err);
	/* ... and Nordic class IDs are supported */
	assert_nordic_classes();
	/* ... and sample root class is supported */
	assert_sample_root_class();

	/* ... and NVV area is corrupted after initialization*/
	erase_area_app_nvv();

	uint8_t constants[SUIT_STORAGE_NVV_N_VARS] = {
		0x00, 0x00, 0x00, 0x00, 0xAA, 0xAA, 0xAA, 0xAA,
		0xAA, 0x55, 0xAA, 0x55, 0x00, 0x00, 0x00, 0x01,
		0x01, 0x00, 0x00, 0x00, 0xFF, 0xFF, 0xFF, 0xFF,
		0xAB, 0xCD, 0xEF, 0x98, 0xFF, 0xFF, 0xFF, 0xFF,
	};
	for (size_t i = 0; i < SUIT_STORAGE_NVV_N_VARS; i++) {
		uint8_t value;

		/* WHEN the NVV value is read */
		err = suit_storage_var_get(i, &value);
		/* THEN the NVV read succeeds */
		zassert_equal(err, SUIT_PLAT_SUCCESS, "Failed to read NVV at index: %d (%d).", i,
			      err);
		/* ... and NVV backup area is used */
		/* ... and values in NVV area matches the preconfigured constants */
		zassert_equal(value, constants[i], "Invalid NVV value at index: %d (0x%X != 0x%X).",
			      i, value, constants[i]);
	}
}

ZTEST(suit_storage_nrf54h20_nvv_tests, test_app_nvv_ro_write)
{
	/* GIVEN the device is provisioned with application MPI with root config */
	erase_area_nordic();
	write_area_nordic_root();
	erase_area_rad();
	erase_area_app();
	write_area_app_root();
	/* .. and NVV is present */
	write_area_app_nvv();
	/* .. and NVV backup is present */
	write_area_app_nvv_backup();

	/* ... and storage module is initialized */
	int err = suit_storage_init();

	/* ... and digest of the application MPI matches... */
	/* ... and the application MPI is the same as application backup area */
	assert_valid_mpi_area_app(SUIT_STORAGE_APP_ADDRESS,
				  SUIT_STORAGE_APP_MPI_SIZE + SUIT_STORAGE_DIGEST_SIZE);
	assert_valid_mpi_area_app(SUIT_STORAGE_NORDIC_ADDRESS + SUIT_STORAGE_RAD_MPI_SIZE +
					  SUIT_STORAGE_DIGEST_SIZE,
				  SUIT_STORAGE_APP_MPI_SIZE + SUIT_STORAGE_DIGEST_SIZE);
	/* ... and parsing of the root MPI succeeds */
	int exp_err = SUIT_PLAT_SUCCESS;
	/* ... and NVV area digest matches */
	/* ... and NVV area is not modified */
	zassert_mem_equal(SUIT_STORAGE_APP_NVV_ADDRESS, nvv_sample, SUIT_STORAGE_APP_NVV_SIZE / 2);
	/* ... and NVV area backup is not modified */
	zassert_mem_equal(SUIT_STORAGE_APP_NVV_ADDRESS + SUIT_STORAGE_APP_NVV_SIZE / 2, nvv_sample,
			  SUIT_STORAGE_APP_NVV_SIZE / 2);
	/* ... and initialization succeeds */
	zassert_equal(err, exp_err, "Failed to initialize SUIT storage (%d).", err);
	/* ... and Nordic class IDs are supported */
	assert_nordic_classes();
	/* ... and sample root class is supported */
	assert_sample_root_class();

	/* ... and NVV area is corrupted after initialization*/
	erase_area_app_nvv();

	/* WHEN NVV variable is updated */
	err = suit_storage_var_set(0, 0xAB);

	/* THEN the NVV update fails */
	zassert_equal(err, SUIT_PLAT_ERR_IO, "NVV corrupted by writing to the read-only area");

	/* ... and NVV backup is not updated */
	zassert_mem_equal(SUIT_STORAGE_APP_NVV_ADDRESS + SUIT_STORAGE_APP_NVV_SIZE / 2, nvv_sample,
			  SUIT_STORAGE_APP_NVV_SIZE / 2);
}
```

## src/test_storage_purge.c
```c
/*
 * Copyright (c) 2024 Nordic Semiconductor ASA
 *
 * SPDX-License-Identifier: LicenseRef-Nordic-5-Clause
 */

#include <zephyr/ztest.h>
#include <suit_storage.h>
#include <suit_storage_mpi.h>
#include <suit_storage_nvv.h>
#include "test_common.h"

ZTEST_SUITE(suit_storage_nrf54h20_bare_recovery_tests, NULL, NULL, NULL, NULL, NULL);

static void assert_app_purged(void)
{
	/* ASSERT that the application MPI area is purged */
	assert_purged_mpi_area_app(SUIT_STORAGE_APP_ADDRESS,
				   SUIT_STORAGE_APP_MPI_SIZE + SUIT_STORAGE_DIGEST_SIZE);
	/* ... and the application MPI backup is purged */
	assert_purged_mpi_area_app(SUIT_STORAGE_NORDIC_ADDRESS + SUIT_STORAGE_RAD_MPI_SIZE +
					   SUIT_STORAGE_DIGEST_SIZE,
				   SUIT_STORAGE_APP_MPI_SIZE + SUIT_STORAGE_DIGEST_SIZE);
	/* ... and the application reserved area as well as update candidate is purged */
	assert_purged_reserved_uci_area_app(SUIT_STORAGE_APP_ADDRESS + SUIT_STORAGE_APP_MPI_SIZE +
						    SUIT_STORAGE_DIGEST_SIZE,
					    SUIT_STORAGE_APP_RFU_SIZE + SUIT_STORAGE_APP_UCI_SIZE);

	/* ... and NVV area digest does not match */
	/* ... and NVV area is initialized with default values (0xFF) and digest */
	zassert_mem_equal(SUIT_STORAGE_APP_NVV_ADDRESS, nvv_empty, SUIT_STORAGE_APP_NVV_SIZE / 2);
	/* ... and NVV area is copied into NVV backup area */
	zassert_mem_equal(SUIT_STORAGE_APP_NVV_ADDRESS + SUIT_STORAGE_APP_NVV_SIZE / 2, nvv_empty,
			  SUIT_STORAGE_APP_NVV_SIZE / 2);
}

static void assert_rad_purged(void)
{
	/* ASSERT that the radio MPI area is purged */
	assert_purged_mpi_area_rad(SUIT_STORAGE_RAD_ADDRESS,
				   SUIT_STORAGE_RAD_MPI_SIZE + SUIT_STORAGE_DIGEST_SIZE);
	/* ... and the radio MPI backup is purged */
	assert_purged_mpi_area_rad(SUIT_STORAGE_NORDIC_ADDRESS,
				   SUIT_STORAGE_RAD_MPI_SIZE + SUIT_STORAGE_DIGEST_SIZE);
}

ZTEST(suit_storage_nrf54h20_bare_recovery_tests, test_storage_purge_populated_storage)
{
	suit_plat_mreg_t update_candidate[1] = {{
		.mem = (uint8_t *)0xCAFEFECA,
		.size = 2044,
	}};

	/* GIVEN the device was provisioned with application and radio MPI with root and sample
	 * radio config
	 */
	erase_area_nordic();
	write_area_nordic_root();
	write_area_nordic_rad();
	/* ... and the MPI area matches the MPI backups */
	erase_area_rad();
	erase_area_app();
	write_area_app_root();
	write_area_rad();
	/* ... and NVV is present */
	write_area_app_nvv();
	/* ... and NVV backup is present */
	write_area_app_nvv_backup();
	/* ... and the update candidate information is present */
	zassert_equal(suit_storage_update_cand_set(update_candidate, ARRAY_SIZE(update_candidate)),
		      SUIT_PLAT_SUCCESS, "Failed to set update candidate information");

	/* WHEN storage application area is purged on uninitialized module */
	int err = suit_storage_purge(SUIT_MANIFEST_DOMAIN_APP);

	/* THEN the purge operation succeeds... */
	zassert_equal(err, SUIT_PLAT_SUCCESS, "Failed to purge application area (%d).", err);

	/* ... and all fields assigned to the application domain are purged */
	assert_app_purged();
	/* ... and the root manifest is not provisioned */
	/* ... and the radio manifest is provisioned */
	assert_sample_rad_class();
	/* ... and digest of the radio MPI matches... */
	assert_valid_mpi_area_rad(SUIT_STORAGE_RAD_ADDRESS,
				  SUIT_STORAGE_RAD_MPI_SIZE + SUIT_STORAGE_DIGEST_SIZE);
	/* ... and the radio MPI backup is still present */
	assert_valid_mpi_area_rad(SUIT_STORAGE_NORDIC_ADDRESS,
				  SUIT_STORAGE_RAD_MPI_SIZE + SUIT_STORAGE_DIGEST_SIZE);
	/* ... and Nordic class IDs are supported */
	assert_nordic_classes();

	/* WHEN storage radio area is purged afterwards */
	err = suit_storage_purge(SUIT_MANIFEST_DOMAIN_RAD);

	/* THEN the purge operation succeeds... */
	zassert_equal(err, SUIT_PLAT_SUCCESS, "Failed to purge radio area (%d).", err);
	/* ... and all fields assigned to the application domain are still purged */
	assert_app_purged();
	/* ... and all fields assigned to the radio domain are purged */
	assert_rad_purged();
	/* ... and only Nordic class IDs are supported */
	assert_only_nordic_classes();
}

ZTEST(suit_storage_nrf54h20_bare_recovery_tests, test_storage_purge_populated_storage_rad_first)
{
	suit_plat_mreg_t update_candidate[1] = {{
		.mem = (uint8_t *)0xCAFEFECA,
		.size = 2044,
	}};

	/* GIVEN the device was provisioned with application and radio MPI with root and sample
	 * radio config
	 */
	erase_area_nordic();
	write_area_nordic_root();
	write_area_nordic_rad();
	/* ... and the MPI area matches the MPI backups */
	erase_area_rad();
	erase_area_app();
	write_area_app_root();
	write_area_rad();
	/* ... and NVV is present */
	write_area_app_nvv();
	/* ... and NVV backup is present */
	write_area_app_nvv_backup();
	/* ... and the update candidate information is present */
	zassert_equal(suit_storage_update_cand_set(update_candidate, ARRAY_SIZE(update_candidate)),
		      SUIT_PLAT_SUCCESS, "Failed to set update candidate information");

	/* WHEN storage radio area is purged */
	int err = suit_storage_purge(SUIT_MANIFEST_DOMAIN_RAD);

	/* THEN the purge operation succeeds... */
	zassert_equal(err, SUIT_PLAT_SUCCESS, "Failed to purge radio area (%d).", err);

	/* ... and all fields assigned to the radio domain are purged */
	assert_rad_purged();
	/* ... and the radio manifest is not provisioned */
	/* ... and the root manifest is provisioned */
	assert_sample_root_class();
	/* ... and digest of the application MPI matches... */
	assert_valid_mpi_area_app(SUIT_STORAGE_APP_ADDRESS,
				  SUIT_STORAGE_APP_MPI_SIZE + SUIT_STORAGE_DIGEST_SIZE);
	/* ... and the application MPI backup is still present */
	assert_valid_mpi_area_app(SUIT_STORAGE_NORDIC_ADDRESS + SUIT_STORAGE_RAD_MPI_SIZE +
					  SUIT_STORAGE_DIGEST_SIZE,
				  SUIT_STORAGE_APP_MPI_SIZE + SUIT_STORAGE_DIGEST_SIZE);

	/* ... and the update candidate information is still present */
	const suit_plat_mreg_t *update_regions = NULL;
	size_t update_regions_len = 0;

	err = suit_storage_update_cand_get(&update_regions, &update_regions_len);
	zassert_equal(err, SUIT_PLAT_SUCCESS,
		      "Update candidate purged as part of radio domain purge.");
	zassert_equal(update_regions_len, 1, "Length of update candidate regions is invalid (%d).",
		      update_regions_len);
	for (size_t i = 0; i < ARRAY_SIZE(update_candidate); i++) {
		zassert_equal(update_regions[i].mem, update_candidate[i].mem,
			      "Update region %d set with wrong address (%p != %p)", i,
			      update_regions[i].mem, update_candidate[i].mem);
		zassert_equal(update_regions[i].size, update_candidate[i].size,
			      "Update region %d set with wrong size (0x%x != 0x%x)", i,
			      update_regions[i].size, update_candidate[i].size);
	}

	/* ... and the NVVs are still present */
	uint8_t constants[SUIT_STORAGE_NVV_N_VARS] = {
		0x00, 0x00, 0x00, 0x00, 0xAA, 0xAA, 0xAA, 0xAA,
		0xAA, 0x55, 0xAA, 0x55, 0x00, 0x00, 0x00, 0x01,
		0x01, 0x00, 0x00, 0x00, 0xFF, 0xFF, 0xFF, 0xFF,
		0xAB, 0xCD, 0xEF, 0x98, 0xFF, 0xFF, 0xFF, 0xFF,
	};

	for (size_t i = 0; i < SUIT_STORAGE_NVV_N_VARS; i++) {
		uint8_t value;

		/* WHEN the NVV value is read */
		err = suit_storage_var_get(i, &value);
		/* THEN the NVV read succeeds */
		zassert_equal(err, SUIT_PLAT_SUCCESS, "Failed to read NVV at index: %d (%d).", i,
			      err);
		/* ... and values in NVV area matches the preconfigured constants */
		zassert_equal(value, constants[i], "Invalid NVV value at index: %d (0x%X != 0x%X).",
			      i, value, constants[i]);
	}

	/* ... and Nordic class IDs are supported */
	assert_nordic_classes();

	/* WHEN storage application area is purged afterwards */
	err = suit_storage_purge(SUIT_MANIFEST_DOMAIN_APP);

	/* THEN the purge operation succeeds... */
	zassert_equal(err, SUIT_PLAT_SUCCESS, "Failed to purge application area (%d).", err);
	/* ... and all fields assigned to the application domain are purged */
	assert_app_purged();
	/* ... and all fields assigned to the radio domain are still purged */
	assert_rad_purged();
	/* ... and only Nordic class IDs are supported */
	assert_only_nordic_classes();
}

ZTEST(suit_storage_nrf54h20_bare_recovery_tests, test_storage_purge_empty_storage)
{
	/* GIVEN storage area is not initialized */
	erase_area_nordic();
	erase_area_rad();
	erase_area_app();

	/* WHEN storage radio area is purged */
	int err = suit_storage_purge(SUIT_MANIFEST_DOMAIN_RAD);

	/* THEN the purge operation succeeds... */
	zassert_equal(err, SUIT_PLAT_SUCCESS, "Failed to purge radio area (%d).", err);

	/* ... and all fields assigned to the application domain are purged */
	assert_app_purged();
	/* ... and all fields assigned to the radio domain are purged */
	assert_rad_purged();
	/* ... and only Nordic class IDs are supported */
	assert_only_nordic_classes();

	/* WHEN storage application area is purged afterwards */
	err = suit_storage_purge(SUIT_MANIFEST_DOMAIN_APP);

	/* THEN the purge operation succeeds... */
	zassert_equal(err, SUIT_PLAT_SUCCESS, "Failed to purge application area (%d).", err);
	/* ... and all fields assigned to the application domain are still purged */
	assert_app_purged();
	/* ... and all fields assigned to the radio domain are still purged */
	assert_rad_purged();
	/* ... and only Nordic class IDs are supported */
	assert_only_nordic_classes();
}

ZTEST(suit_storage_nrf54h20_bare_recovery_tests, test_storage_purge_update_only)
{
	suit_plat_mreg_t update_candidate[1] = {{
		.mem = (uint8_t *)0xCAFEFECA,
		.size = 2044,
	}};

	/* GIVEN the storage contains only the update candidate information */
	erase_area_nordic();
	erase_area_rad();
	erase_area_app();
	zassert_equal(suit_storage_update_cand_set(update_candidate, ARRAY_SIZE(update_candidate)),
		      SUIT_PLAT_SUCCESS, "Failed to set update candidate information");

	/* WHEN storage application area is purged */
	int err = suit_storage_purge(SUIT_MANIFEST_DOMAIN_APP);

	/* THEN the purge operation succeeds... */
	zassert_equal(err, SUIT_PLAT_SUCCESS, "Failed to purge application area (%d).", err);
	/* ... and all fields assigned to the application domain are purged */
	assert_app_purged();
	/* ... and all fields assigned to the radio domain are purged */
	assert_rad_purged();
	/* ... and only Nordic class IDs are supported */
	assert_only_nordic_classes();
}
```
